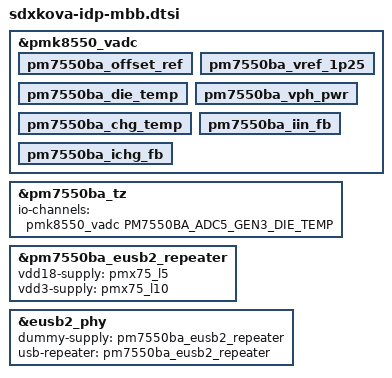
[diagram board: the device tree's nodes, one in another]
// SPDX-License-Identifier: BSD-3-Clause
/*
 * Copyright (c) 2024 Qualcomm Innovation Center, Inc. All rights reserved.
 */

#include "sdxkova-pmic-overlay.dtsi"
#include "pm7550ba.dtsi"

&pmk8550_vadc {
	/* PM8550BA Channel nodes */
	pm7550ba_offset_ref {
		status = "ok";
	};

	pm7550ba_vref_1p25 {
		status = "ok";
	};

	pm7550ba_die_temp {
		status = "ok";
	};

	pm7550ba_vph_pwr {
		status = "ok";
	};

	pm7550ba_chg_temp {
		status = "ok";
	};

	pm7550ba_iin_fb {
		status = "ok";
	};

	pm7550ba_ichg_fb {
		status = "ok";
	};
};

&pm7550ba_tz {
	io-channels = <&pmk8550_vadc PM7550BA_ADC5_GEN3_DIE_TEMP>;
	io-channel-names = "thermal";
};

&pm7550ba_eusb2_repeater {
	vdd18-supply = <&pmx75_l5>;
	vdd3-supply = <&pmx75_l10>;
	status = "ok";
};

&eusb2_phy {
	dummy-supply = <&pm7550ba_eusb2_repeater>;
	usb-repeater = <&pm7550ba_eusb2_repeater>;
};
